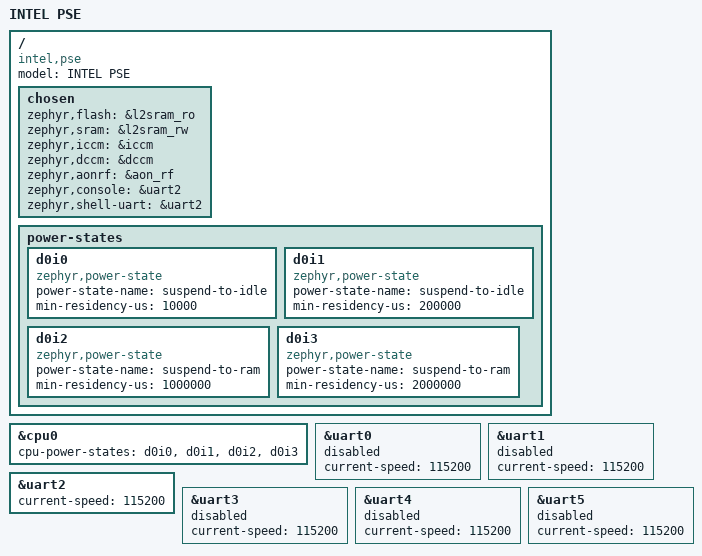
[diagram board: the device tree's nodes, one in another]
/*
 * Copyright (c) 2021 Intel Corporation
 *
 * SPDX-License-Identifier: Apache-2.0
 */

/dts-v1/;
#include <intel/pse.dtsi>

/ {
	model = "INTEL PSE";
	compatible = "intel,pse";

	chosen {
		zephyr,flash = &l2sram_ro;
		zephyr,sram = &l2sram_rw;
		zephyr,iccm = &iccm;
		zephyr,dccm = &dccm;
		zephyr,aonrf = &aon_rf;
		zephyr,console = &uart2;
		zephyr,shell-uart = &uart2;
	};

	power-states {
		d0i0: d0i0 {
			compatible = "zephyr,power-state";
			power-state-name = "suspend-to-idle";
			min-residency-us = <10000>;
		};

		d0i1: d0i1 {
			compatible = "zephyr,power-state";
			power-state-name = "suspend-to-idle";
			min-residency-us = <200000>;
		};

		d0i2: d0i2 {
			compatible = "zephyr,power-state";
			power-state-name = "suspend-to-ram";
			min-residency-us = <1000000>;
		};

		d0i3: d0i3 {
			compatible = "zephyr,power-state";
			power-state-name = "suspend-to-ram";
			min-residency-us = <2000000>;
		};
	};

};

&cpu0 {
	cpu-power-states = <&d0i0 &d0i1 &d0i2 &d0i3>;
};

&uart0 {
	current-speed = <115200>;
	status = "disabled";
};

&uart1 {
	current-speed = <115200>;
	status = "disabled";
};

&uart2 {
	current-speed = <115200>;
	status = "okay";
};

&uart3 {
	current-speed = <115200>;
	status = "disabled";
};

&uart4 {
	current-speed = <115200>;
	status = "disabled";
};

&uart5 {
	current-speed = <115200>;
	status = "disabled";
};
